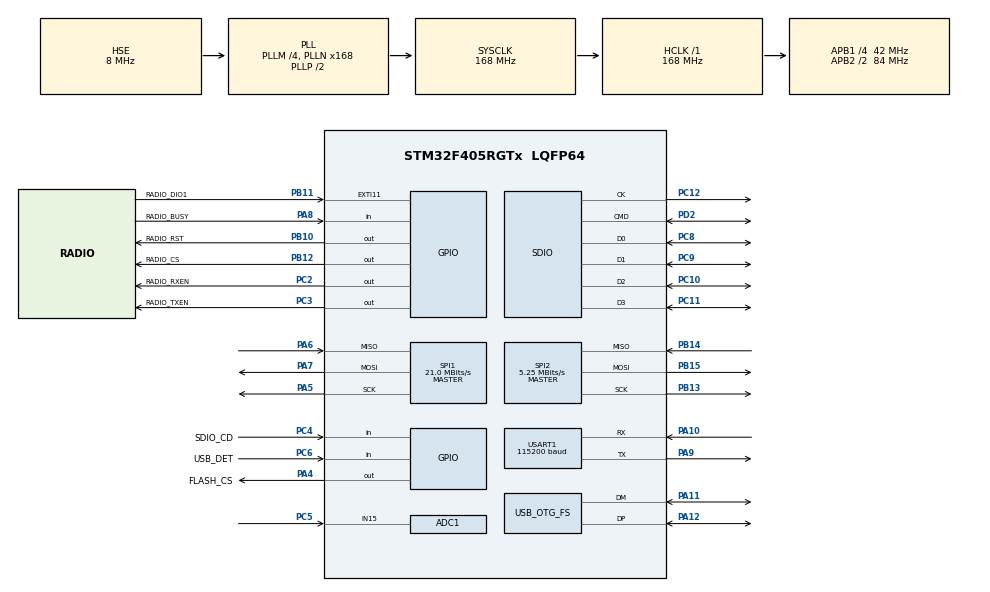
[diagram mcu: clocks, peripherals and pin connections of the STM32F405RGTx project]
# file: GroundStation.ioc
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ADC1.Channel-0\#ChannelRegularConversion=ADC_CHANNEL_15
ADC1.NbrOfConversionFlag=1
ADC1.Rank-0\#ChannelRegularConversion=1
ADC1.SamplingTime-0\#ChannelRegularConversion=ADC_SAMPLETIME_144CYCLES
ADC1.master=1
Dma.Request0=SDIO_RX
Dma.Request1=SDIO_TX
Dma.SDIO_RX.0.Direction=DMA_PERIPH_TO_MEMORY
Dma.SDIO_RX.0.FIFOMode=DMA_FIFOMODE_ENABLE
Dma.SDIO_RX.0.FIFOThreshold=DMA_FIFO_THRESHOLD_FULL
Dma.SDIO_RX.0.Instance=DMA2_Stream3
Dma.SDIO_RX.0.MemBurst=DMA_MBURST_INC4
Dma.SDIO_RX.0.MemDataAlignment=DMA_MDATAALIGN_WORD
Dma.SDIO_RX.0.MemInc=DMA_MINC_ENABLE
Dma.SDIO_RX.0.Mode=DMA_PFCTRL
Dma.SDIO_RX.0.PeriphBurst=DMA_PBURST_INC4
Dma.SDIO_RX.0.PeriphDataAlignment=DMA_PDATAALIGN_WORD
Dma.SDIO_RX.0.PeriphInc=DMA_PINC_DISABLE
Dma.SDIO_RX.0.Priority=DMA_PRIORITY_LOW
Dma.SDIO_TX.1.Direction=DMA_MEMORY_TO_PERIPH
Dma.SDIO_TX.1.FIFOMode=DMA_FIFOMODE_ENABLE
Dma.SDIO_TX.1.FIFOThreshold=DMA_FIFO_THRESHOLD_FULL
Dma.SDIO_TX.1.Instance=DMA2_Stream6
Dma.SDIO_TX.1.MemBurst=DMA_MBURST_INC4
Dma.SDIO_TX.1.MemDataAlignment=DMA_MDATAALIGN_WORD
Dma.SDIO_TX.1.MemInc=DMA_MINC_ENABLE
Dma.SDIO_TX.1.Mode=DMA_PFCTRL
Dma.SDIO_TX.1.PeriphBurst=DMA_PBURST_INC4
Dma.SDIO_TX.1.PeriphDataAlignment=DMA_PDATAALIGN_WORD
Dma.SDIO_TX.1.PeriphInc=DMA_PINC_DISABLE
Dma.SDIO_TX.1.Priority=DMA_PRIORITY_LOW
FATFS.BSP.number=1
FATFS0.BSP.STBoard=false
FATFS0.BSP.api=Unknown
FATFS0.BSP.instance=PC4
FATFS0.BSP.ip=GPIO
FATFS0.BSP.mode=Input
FATFS0.BSP.name=Detect_SDIO
FATFS0.BSP.solution=PC4
FREERTOS.Tasks01=defaultTask,24,512,StartDefaultTask,Default,NULL,Dynamic,NULL,NULL
Mcu.Family=STM32F4
Mcu.Name=STM32F405RGTx
Mcu.Package=LQFP64
NVIC.DMA2_Stream3_IRQn=true\:5\:0\:false\:false\:true\:true\:false\:true\:true
NVIC.DMA2_Stream6_IRQn=true\:5\:0\:false\:false\:true\:true\:false\:true\:true
NVIC.EXTI15_10_IRQn=true\:5\:0\:false\:false\:true\:true\:true\:true\:true
NVIC.OTG_FS_IRQn=true\:5\:0\:false\:false\:true\:true\:false\:true\:true
NVIC.PriorityGroup=NVIC_PRIORITYGROUP_4
NVIC.SDIO_IRQn=true\:5\:0\:false\:false\:true\:true\:true\:true\:true
NVIC.TIM8_TRG_COM_TIM14_IRQn=true\:15\:0\:false\:false\:true\:false\:false\:true\:true
NVIC.TimeBase=TIM8_TRG_COM_TIM14_IRQn
NVIC.TimeBaseIP=TIM14
PA10.Mode=Asynchronous
PA10.Signal=USART1_RX
PA11.Mode=Device_Only
PA11.Signal=USB_OTG_FS_DM
PA12.Mode=Device_Only
PA12.Signal=USB_OTG_FS_DP
PA13.Mode=Serial_Wire
PA13.Signal=SYS_JTMS-SWDIO
PA14.Mode=Serial_Wire
PA14.Signal=SYS_JTCK-SWCLK
PA4.GPIO_Label=FLASH_CS
PA4.GPIO_PuPd=GPIO_NOPULL
PA4.GPIO_Speed=GPIO_SPEED_FREQ_HIGH
PA4.PinState=GPIO_PIN_SET
PA4.Signal=GPIO_Output
PA5.Mode=Full_Duplex_Master
PA5.Signal=SPI1_SCK
PA6.Mode=Full_Duplex_Master
PA6.Signal=SPI1_MISO
PA7.Mode=Full_Duplex_Master
PA7.Signal=SPI1_MOSI
PA8.GPIO_Label=RADIO_BUSY
PA8.GPIO_PuPd=GPIO_PULLDOWN
PA8.Signal=GPIO_Input
PA9.Mode=Asynchronous
PA9.Signal=USART1_TX
PB10.GPIO_Label=RADIO_RST
PB10.PinState=GPIO_PIN_RESET
PB10.Signal=GPIO_Output
PB11.GPIO_Label=RADIO_DIO1
PB11.GPIO_PuPd=GPIO_PULLDOWN
PB11.Signal=GPXTI11
PB12.GPIO_Label=RADIO_CS
PB12.GPIO_Speed=GPIO_SPEED_FREQ_HIGH
PB12.PinState=GPIO_PIN_SET
PB12.Signal=GPIO_Output
PB13.Mode=Full_Duplex_Master
PB13.Signal=SPI2_SCK
PB14.Mode=Full_Duplex_Master
PB14.Signal=SPI2_MISO
PB15.Mode=Full_Duplex_Master
PB15.Signal=SPI2_MOSI
PC10.Mode=SD_4_bits_Wide_bus
PC10.Signal=SDIO_D2
PC11.Mode=SD_4_bits_Wide_bus
PC11.Signal=SDIO_D3
PC12.Mode=SD_4_bits_Wide_bus
PC12.Signal=SDIO_CK
PC2.GPIO_Label=RADIO_RXEN
PC2.Signal=GPIO_Output
PC3.GPIO_Label=RADIO_TXEN
PC3.Signal=GPIO_Output
PC4.GPIO_Label=SDIO_CD
PC4.GPIO_PuPd=GPIO_PULLUP
PC4.Signal=GPIO_Input
PC5.Signal=ADCx_IN15
PC6.GPIO_Label=USB_DET
PC6.GPIO_PuPd=GPIO_NOPULL
PC6.Signal=GPIO_Input
PC8.Mode=SD_4_bits_Wide_bus
PC8.Signal=SDIO_D0
PC9.Mode=SD_4_bits_Wide_bus
PC9.Signal=SDIO_D1
PD2.Mode=SD_4_bits_Wide_bus
PD2.Signal=SDIO_CMD
PH0-OSC_IN.Mode=HSE-External-Clock-Source
PH0-OSC_IN.Signal=RCC_OSC_IN
PH1-OSC_OUT.Mode=HSE-External-Clock-Source
PH1-OSC_OUT.Signal=RCC_OSC_OUT
ProjectManager.HeapSize=0x200
ProjectManager.StackSize=0x400
ProjectManager.TargetToolchain=CMake
RCC.48MHZClocksFreq_Value=48000000
RCC.AHBFreq_Value=168000000
RCC.APB1CLKDivider=RCC_HCLK_DIV4
RCC.APB1Freq_Value=42000000
RCC.APB1TimFreq_Value=84000000
RCC.APB2CLKDivider=RCC_HCLK_DIV2
RCC.APB2Freq_Value=84000000
RCC.APB2TimFreq_Value=168000000
RCC.CortexFreq_Value=168000000
RCC.HCLKFreq_Value=168000000
RCC.HSE_VALUE=8000000
RCC.HSI_VALUE=16000000
RCC.LSE_VALUE=32768
RCC.PLLM=4
RCC.PLLN=168
RCC.PLLQ=7
RCC.SYSCLKFreq_VALUE=168000000
RCC.SYSCLKSource=RCC_SYSCLKSOURCE_PLLCLK
RCC.VCOOutputFreq_Value=336000000
SDIO.ClockDiv=10
SH.ADCx_IN15.0=ADC1_IN15,IN15
SPI1.BaudRatePrescaler=SPI_BAUDRATEPRESCALER_4
SPI1.CalculateBaudRate=21.0 MBits/s
SPI1.Direction=SPI_DIRECTION_2LINES
SPI1.Mode=SPI_MODE_MASTER
SPI1.VirtualType=VM_MASTER
SPI2.BaudRatePrescaler=SPI_BAUDRATEPRESCALER_8
SPI2.CalculateBaudRate=5.25 MBits/s
SPI2.Direction=SPI_DIRECTION_2LINES
SPI2.Mode=SPI_MODE_MASTER
SPI2.VirtualType=VM_MASTER
USART1.BaudRate=115200
USART1.VirtualMode=VM_ASYNC
USB_DEVICE.CLASS_NAME_FS=CDC
USB_DEVICE.VirtualMode-CDC_FS=Cdc
USB_DEVICE.VirtualModeFS=Cdc_FS
USB_OTG_FS.VirtualMode=Device_Only
VP_FATFS_VS_SDIO.Mode=SDIO
VP_FREERTOS_VS_CMSIS_V2.Mode=CMSIS_V2
VP_SYS_VS_tim14.Mode=TIM14
VP_USB_DEVICE_VS_USB_DEVICE_CDC_FS.Mode=CDC_FS
board=custom

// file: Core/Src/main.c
/* USER CODE BEGIN Header */
/**
  ******************************************************************************
  * @file           : main.c
  * @brief          : Main program body
  ******************************************************************************
  * @attention
  *
  * Copyright (c) 2026 STMicroelectronics.
  * All rights reserved.
  *
  * This software is licensed under terms that can be found in the LICENSE file
  * in the root directory of this software component.
  * If no LICENSE file comes with this software, it is provided AS-IS.
  *
  ******************************************************************************
  */
/* USER CODE END Header */
#include "main.h"
#include "cmsis_os.h"
#include "adc.h"
#include "dma.h"
#include "fatfs.h"
#include "sdio.h"
#include "spi.h"
#include "usart.h"
#include "usb_device.h"
#include "gpio.h"

/* USER CODE BEGIN Includes */
#include "ground_station_app.h"

/* USER CODE END Includes */

void SystemClock_Config(void);
void MX_FREERTOS_Init(void);

int main(void)
{

  /* MCU Configuration--------------------------------------------------------*/

  /* Reset of all peripherals, Initializes the Flash interface and the Systick. */
  HAL_Init();

  /* USER CODE BEGIN Init */
  GroundStationApp_EarlySafetyInit();

  /* USER CODE END Init */

  /* Configure the system clock */
  SystemClock_Config();

  /* Initialize all configured peripherals */
  MX_GPIO_Init();
  MX_DMA_Init();
  MX_SDIO_SD_Init();
  MX_ADC1_Init();
  MX_SPI1_Init();
  MX_SPI2_Init();
  MX_USART1_UART_Init();
  MX_FATFS_Init();

  /* Init scheduler */
  osKernelInitialize();  /* Call init function for freertos objects (in cmsis_os2.c) */
  MX_FREERTOS_Init();

  /* Start scheduler */
  osKernelStart();

  /* We should never get here as control is now taken by the scheduler */

  /* Infinite loop */
  while (1)
  {

  }
}

void SystemClock_Config(void)
{
  RCC_OscInitTypeDef RCC_OscInitStruct = {0};
  RCC_ClkInitTypeDef RCC_ClkInitStruct = {0};

  /** Configure the main internal regulator output voltage
  */
  __HAL_RCC_PWR_CLK_ENABLE();
  __HAL_PWR_VOLTAGESCALING_CONFIG(PWR_REGULATOR_VOLTAGE_SCALE1);

  /** Initializes the RCC Oscillators according to the specified parameters
  * in the RCC_OscInitTypeDef structure.
  */
  RCC_OscInitStruct.OscillatorType = RCC_OSCILLATORTYPE_HSE;
  RCC_OscInitStruct.HSEState = RCC_HSE_BYPASS;
  RCC_OscInitStruct.PLL.PLLState = RCC_PLL_ON;
  RCC_OscInitStruct.PLL.PLLSource = RCC_PLLSOURCE_HSE;
  RCC_OscInitStruct.PLL.PLLM = 4;
  RCC_OscInitStruct.PLL.PLLN = 168;
  RCC_OscInitStruct.PLL.PLLP = RCC_PLLP_DIV2;
  RCC_OscInitStruct.PLL.PLLQ = 7;
  if (HAL_RCC_OscConfig(&RCC_OscInitStruct) != HAL_OK)
  {
    Error_Handler();
  }

  /** Initializes the CPU, AHB and APB buses clocks
  */
  RCC_ClkInitStruct.ClockType = RCC_CLOCKTYPE_HCLK|RCC_CLOCKTYPE_SYSCLK
                              |RCC_CLOCKTYPE_PCLK1|RCC_CLOCKTYPE_PCLK2;
  RCC_ClkInitStruct.SYSCLKSource = RCC_SYSCLKSOURCE_PLLCLK;
  RCC_ClkInitStruct.AHBCLKDivider = RCC_SYSCLK_DIV1;
  RCC_ClkInitStruct.APB1CLKDivider = RCC_HCLK_DIV4;
  RCC_ClkInitStruct.APB2CLKDivider = RCC_HCLK_DIV2;

  if (HAL_RCC_ClockConfig(&RCC_ClkInitStruct, FLASH_LATENCY_5) != HAL_OK)
  {
    Error_Handler();
  }
}

void HAL_TIM_PeriodElapsedCallback(TIM_HandleTypeDef *htim)
{
  if (htim->Instance == TIM14)
  {
    HAL_IncTick();
  }
}

void Error_Handler(void)
{
  __disable_irq();
  while (1)
  {
  }
}

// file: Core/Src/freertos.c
/* USER CODE BEGIN Header */
/**
  ******************************************************************************
  * File Name          : freertos.c
  * Description        : Code for freertos applications
  ******************************************************************************
  * @attention
  *
  * Copyright (c) 2026 STMicroelectronics.
  * All rights reserved.
  *
  * This software is licensed under terms that can be found in the LICENSE file
  * in the root directory of this software component.
  * If no LICENSE file comes with this software, it is provided AS-IS.
  *
  ******************************************************************************
  */
/* USER CODE END Header */

#include "FreeRTOS.h"
#include "task.h"
#include "main.h"
#include "cmsis_os.h"

/* USER CODE BEGIN Includes */
#include "ground_station_app.h"

/* USER CODE END Includes */

/* Definitions for defaultTask */
osThreadId_t defaultTaskHandle;
const osThreadAttr_t defaultTask_attributes = {
  .name = "defaultTask",
  .stack_size = 512 * 4,
  .priority = (osPriority_t) osPriorityNormal,
};

void StartDefaultTask(void *argument);

extern void MX_USB_DEVICE_Init(void);
void MX_FREERTOS_Init(void); /* (MISRA C 2004 rule 8.1) */

void MX_FREERTOS_Init(void) {

  /* Create the thread(s) */
  /* creation of defaultTask */
  defaultTaskHandle = osThreadNew(StartDefaultTask, NULL, &defaultTask_attributes);

}

void StartDefaultTask(void *argument)
{
  /* init code for USB_DEVICE */
  MX_USB_DEVICE_Init();
  /* USER CODE BEGIN StartDefaultTask */
  GroundStationApp_Run();
  /* USER CODE END StartDefaultTask */
}
